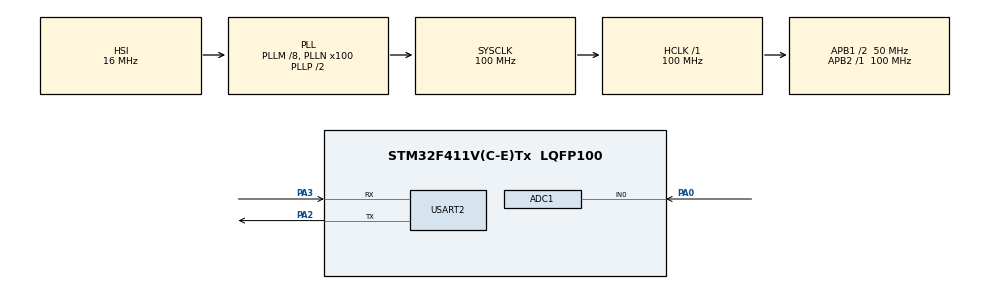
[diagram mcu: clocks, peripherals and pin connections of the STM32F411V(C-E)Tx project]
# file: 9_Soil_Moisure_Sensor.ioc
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Mcu.Family=STM32F4
Dma.ADC1.0.Instance=DMA2_Stream0
RCC.CortexFreq_Value=100000000
ADC1.Rank-0\#ChannelRegularConversion=1
ADC1.ContinuousConvMode=ENABLE
PH1\ -\ OSC_OUT.Mode=HSE-External-Oscillator
RCC.APB1CLKDivider=RCC_HCLK_DIV2
RCC.SYSCLKSource=RCC_SYSCLKSOURCE_PLLCLK
ProjectManager.StackSize=0x400
PA0-WKUP.Signal=ADCx_IN0
PA13.Signal=SYS_JTMS-SWDIO
PA3.Mode=Asynchronous
Dma.ADC1.0.PeriphDataAlignment=DMA_PDATAALIGN_HALFWORD
PH0\ -\ OSC_IN.Mode=HSE-External-Oscillator
PH0\ -\ OSC_IN.Signal=RCC_OSC_IN
ProjectManager.TargetToolchain=STM32CubeIDE
Dma.ADC1.0.Mode=DMA_CIRCULAR
RCC.HCLKFreq_Value=100000000
Dma.ADC1.0.Priority=DMA_PRIORITY_LOW
RCC.APB2TimFreq_Value=100000000
Dma.ADC1.0.Direction=DMA_PERIPH_TO_MEMORY
NVIC.DMA2_Stream0_IRQn=true\:0\:0\:false\:false\:true\:false\:true
RCC.LSE_VALUE=32768
Dma.ADC1.0.MemDataAlignment=DMA_MDATAALIGN_HALFWORD
RCC.AHBFreq_Value=100000000
ADC1.Channel-0\#ChannelRegularConversion=ADC_CHANNEL_0
RCC.HSE_VALUE=25000000
PH1\ -\ OSC_OUT.Signal=RCC_OSC_OUT
ADC1.ScanConvMode=ENABLE
board=custom
RCC.VCOOutputFreq_Value=200000000
RCC.APB2Freq_Value=100000000
PA14.Mode=Serial_Wire
Dma.ADC1.0.PeriphInc=DMA_PINC_DISABLE
SH.ADCx_IN0.0=ADC1_IN0,IN0
ADC1.DMAContinuousRequests=ENABLE
PA13.Mode=Serial_Wire
Mcu.Name=STM32F411V(C-E)Tx
ADC1.SamplingTime-0\#ChannelRegularConversion=ADC_SAMPLETIME_144CYCLES
PA2.Signal=USART2_TX
RCC.48MHZClocksFreq_Value=50000000
RCC.SYSCLKFreq_VALUE=100000000
Mcu.Package=LQFP100
ADC1.master=1
USART2.VirtualMode=VM_ASYNC
PA14.Signal=SYS_JTCK-SWCLK
Dma.ADC1.0.MemInc=DMA_MINC_ENABLE
ProjectManager.HeapSize=0x200
RCC.HSI_VALUE=16000000
NVIC.PriorityGroup=NVIC_PRIORITYGROUP_4
ADC1.NbrOfConversionFlag=1
RCC.PLLM=8
RCC.PLLN=100
RCC.APB1TimFreq_Value=100000000
PA2.Mode=Asynchronous
Dma.ADC1.0.FIFOMode=DMA_FIFOMODE_DISABLE
RCC.APB1Freq_Value=50000000
Dma.Request0=ADC1
PA3.Signal=USART2_RX

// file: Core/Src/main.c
/* USER CODE BEGIN Header */
/**
 ******************************************************************************
 * @file           : main.c
 * @brief          : Main program body
 ******************************************************************************
 * @attention
 *
 * <h2><center>&copy; Copyright (c) 2021 STMicroelectronics.
 * All rights reserved.</center></h2>
 *
 * This software component is licensed by ST under BSD 3-Clause license,
 * the "License"; You may not use this file except in compliance with the
 * License. You may obtain a copy of the License at:
 *                        opensource.org/licenses/BSD-3-Clause
 *
 ******************************************************************************
 */
/* USER CODE END Header */
#include "main.h"

/* USER CODE BEGIN Includes */
#include "Uart.h"
/* USER CODE END Includes */

/* USER CODE BEGIN PD */
#define SOIL_WET 1500
#define SOIL_DRY 3000
/* USER CODE END PD */

ADC_HandleTypeDef hadc1;
DMA_HandleTypeDef hdma_adc1;

UART_HandleTypeDef huart2;

/* USER CODE BEGIN PV */
uint32_t adc[1];
/* USER CODE END PV */

void SystemClock_Config(void);
static void MX_GPIO_Init(void);
static void MX_DMA_Init(void);
static void MX_ADC1_Init(void);
static void MX_USART2_UART_Init(void);

int main(void)
{

  /* MCU Configuration--------------------------------------------------------*/

  /* Reset of all peripherals, Initializes the Flash interface and the Systick. */
  HAL_Init();

  /* Configure the system clock */
  SystemClock_Config();

  /* Initialize all configured peripherals */
  MX_GPIO_Init();
  MX_DMA_Init();
  MX_ADC1_Init();
  MX_USART2_UART_Init();
  /* USER CODE BEGIN 2 */
	HAL_ADC_Start_DMA(&hadc1, adc, 1);
  /* USER CODE END 2 */

  /* Infinite loop */
	while (1)
	{

    /* USER CODE BEGIN 3 */
		float virtueVoltage = *adc*3.3f/4095;
		float realisticVoltage = 1.67f*virtueVoltage;
		uint16_t realisticAdc = realisticVoltage*4095/5 ;//Vin = Vref*adc/4098

		SendConstChar("virtue ADC: ", huart2);
		SendUnsignedNumber(*adc, huart2);
		SendConstChar("\n ", huart2);
		SendConstChar("virtue Voltage: ", huart2);
		SendFloatLn(virtueVoltage, huart2);

		SendConstChar("realistic ADC: ", huart2);
		SendUnsignedNumber((uint32_t)realisticAdc, huart2);
		SendConstChar("\n ", huart2);
		SendConstChar("Realistic Voltage: ", huart2);
		SendFloatLn(realisticVoltage, huart2);
		if(realisticAdc < SOIL_WET){
			SendConstCharLn("Soil is too wet", huart2);
		}else if(realisticAdc >= SOIL_WET && realisticAdc < SOIL_DRY){
			SendConstCharLn("Soil moisture is fine", huart2);
		}else{
			SendConstCharLn("Soil is too dry", huart2);
		}
		HAL_Delay(1000);
	}
  /* USER CODE END 3 */
}

void SystemClock_Config(void)
{
  RCC_OscInitTypeDef RCC_OscInitStruct = {0};
  RCC_ClkInitTypeDef RCC_ClkInitStruct = {0};

  /** Configure the main internal regulator output voltage
  */
  __HAL_RCC_PWR_CLK_ENABLE();
  __HAL_PWR_VOLTAGESCALING_CONFIG(PWR_REGULATOR_VOLTAGE_SCALE1);
  /** Initializes the RCC Oscillators according to the specified parameters
  * in the RCC_OscInitTypeDef structure.
  */
  RCC_OscInitStruct.OscillatorType = RCC_OSCILLATORTYPE_HSI;
  RCC_OscInitStruct.HSIState = RCC_HSI_ON;
  RCC_OscInitStruct.HSICalibrationValue = RCC_HSICALIBRATION_DEFAULT;
  RCC_OscInitStruct.PLL.PLLState = RCC_PLL_ON;
  RCC_OscInitStruct.PLL.PLLSource = RCC_PLLSOURCE_HSI;
  RCC_OscInitStruct.PLL.PLLM = 8;
  RCC_OscInitStruct.PLL.PLLN = 100;
  RCC_OscInitStruct.PLL.PLLP = RCC_PLLP_DIV2;
  RCC_OscInitStruct.PLL.PLLQ = 4;
  if (HAL_RCC_OscConfig(&RCC_OscInitStruct) != HAL_OK)
  {
    Error_Handler();
  }
  /** Initializes the CPU, AHB and APB buses clocks
  */
  RCC_ClkInitStruct.ClockType = RCC_CLOCKTYPE_HCLK|RCC_CLOCKTYPE_SYSCLK
                              |RCC_CLOCKTYPE_PCLK1|RCC_CLOCKTYPE_PCLK2;
  RCC_ClkInitStruct.SYSCLKSource = RCC_SYSCLKSOURCE_PLLCLK;
  RCC_ClkInitStruct.AHBCLKDivider = RCC_SYSCLK_DIV1;
  RCC_ClkInitStruct.APB1CLKDivider = RCC_HCLK_DIV2;
  RCC_ClkInitStruct.APB2CLKDivider = RCC_HCLK_DIV1;

  if (HAL_RCC_ClockConfig(&RCC_ClkInitStruct, FLASH_LATENCY_3) != HAL_OK)
  {
    Error_Handler();
  }
}

static void MX_ADC1_Init(void)
{

  ADC_ChannelConfTypeDef sConfig = {0};

  /** Configure the global features of the ADC (Clock, Resolution, Data Alignment and number of conversion)
  */
  hadc1.Instance = ADC1;
  hadc1.Init.ClockPrescaler = ADC_CLOCK_SYNC_PCLK_DIV4;
  hadc1.Init.Resolution = ADC_RESOLUTION_12B;
  hadc1.Init.ScanConvMode = ENABLE;
  hadc1.Init.ContinuousConvMode = ENABLE;
  hadc1.Init.DiscontinuousConvMode = DISABLE;
  hadc1.Init.ExternalTrigConvEdge = ADC_EXTERNALTRIGCONVEDGE_NONE;
  hadc1.Init.ExternalTrigConv = ADC_SOFTWARE_START;
  hadc1.Init.DataAlign = ADC_DATAALIGN_RIGHT;
  hadc1.Init.NbrOfConversion = 1;
  hadc1.Init.DMAContinuousRequests = ENABLE;
  hadc1.Init.EOCSelection = ADC_EOC_SINGLE_CONV;
  if (HAL_ADC_Init(&hadc1) != HAL_OK)
  {
    Error_Handler();
  }
  /** Configure for the selected ADC regular channel its corresponding rank in the sequencer and its sample time.
  */
  sConfig.Channel = ADC_CHANNEL_0;
  sConfig.Rank = 1;
  sConfig.SamplingTime = ADC_SAMPLETIME_144CYCLES;
  if (HAL_ADC_ConfigChannel(&hadc1, &sConfig) != HAL_OK)
  {
    Error_Handler();
  }

}

static void MX_USART2_UART_Init(void)
{

  huart2.Instance = USART2;
  huart2.Init.BaudRate = 115200;
  huart2.Init.WordLength = UART_WORDLENGTH_8B;
  huart2.Init.StopBits = UART_STOPBITS_1;
  huart2.Init.Parity = UART_PARITY_NONE;
  huart2.Init.Mode = UART_MODE_TX_RX;
  huart2.Init.HwFlowCtl = UART_HWCONTROL_NONE;
  huart2.Init.OverSampling = UART_OVERSAMPLING_16;
  if (HAL_UART_Init(&huart2) != HAL_OK)
  {
    Error_Handler();
  }

}

static void MX_DMA_Init(void)
{

  /* DMA controller clock enable */
  __HAL_RCC_DMA2_CLK_ENABLE();

  /* DMA interrupt init */
  /* DMA2_Stream0_IRQn interrupt configuration */
  HAL_NVIC_SetPriority(DMA2_Stream0_IRQn, 0, 0);
  HAL_NVIC_EnableIRQ(DMA2_Stream0_IRQn);

}

static void MX_GPIO_Init(void)
{

  /* GPIO Ports Clock Enable */
  __HAL_RCC_GPIOH_CLK_ENABLE();
  __HAL_RCC_GPIOA_CLK_ENABLE();

}

void Error_Handler(void)
{
	__disable_irq();
	while (1)
	{
	}
}

/************************ (C) COPYRIGHT STMicroelectronics *****END OF FILE****/
